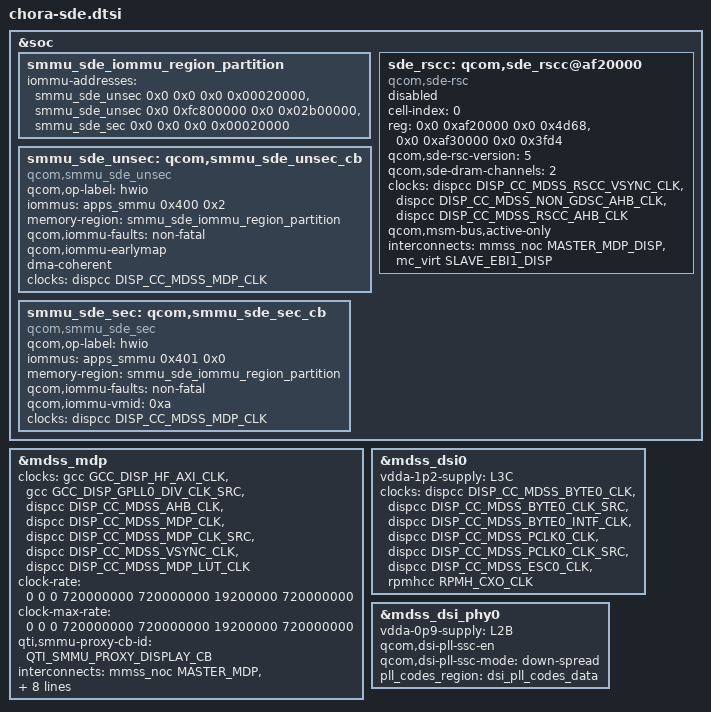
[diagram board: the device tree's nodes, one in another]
// SPDX-License-Identifier: BSD-3-Clause
/*
 * Copyright (c) Qualcomm Technologies, Inc. and/or its subsidiaries.
 */

#include <dt-bindings/interrupt-controller/arm-gic.h>
#include <dt-bindings/soc/qcom,ipcc.h>
#include <dt-bindings/interconnect/qcom,chora.h>
#include <dt-bindings/clock/qcom,chora-dispcc.h>
#include <dt-bindings/clock/qcom,chora-gcc.h>
#include <dt-bindings/clock/qcom,rpmh.h>
#include <dt-bindings/arm/msm/qti-smmu-proxy-dt-ids.h>
#include <dt-bindings/regulator/qcom,rpmh-regulator-levels.h>
#include "chora-sde-common.dtsi"

&soc {
	smmu_sde_iommu_region_partition: smmu_sde_iommu_region_partition {
		iommu-addresses = <&smmu_sde_unsec 0x0 0x0 0x0 0x00020000>,
				  <&smmu_sde_unsec 0x0 0xfc800000 0x0 0x02b00000>,
				  <&smmu_sde_sec 0x0 0x0 0x0 0x00020000>;
	};

	smmu_sde_unsec: qcom,smmu_sde_unsec_cb {
		compatible = "qcom,smmu_sde_unsec";
		qcom,op-label = "hwio";
		status = "ok";
		iommus = <&apps_smmu 0x400 0x2>;
		memory-region = <&smmu_sde_iommu_region_partition>;
		qcom,iommu-faults = "non-fatal";
		qcom,iommu-earlymap; /* for cont-splash */
		dma-coherent;
		clocks = <&dispcc DISP_CC_MDSS_MDP_CLK>;
		clock-names = "mdp_core_clk";
	};

	smmu_sde_sec: qcom,smmu_sde_sec_cb {
		compatible = "qcom,smmu_sde_sec";
		qcom,op-label = "hwio";
		status = "ok";
		iommus = <&apps_smmu 0x401 0x0>;
		memory-region = <&smmu_sde_iommu_region_partition>;
		qcom,iommu-faults = "non-fatal";
		qcom,iommu-vmid = <0xa>;
		clocks = <&dispcc DISP_CC_MDSS_MDP_CLK>;
		clock-names = "mdp_core_clk";
	};

	sde_rscc: qcom,sde_rscc@af20000 {
		cell-index = <0>;
		compatible = "qcom,sde-rsc";
		status = "disabled";
		reg = <0x0 0xaf20000 0x0 0x4d68>,
			<0x0 0xaf30000 0x0 0x3fd4>;
		reg-names = "drv", "wrapper";
		qcom,sde-rsc-version = <5>;

		qcom,sde-dram-channels = <2>;

		clocks = <&dispcc DISP_CC_MDSS_RSCC_VSYNC_CLK>,
			<&dispcc DISP_CC_MDSS_NON_GDSC_AHB_CLK>,
			<&dispcc DISP_CC_MDSS_RSCC_AHB_CLK>;

		clock-names = "vsync_clk", "gdsc_clk", "iface_clk";

		qcom,msm-bus,active-only;
		interconnects = <&mmss_noc MASTER_MDP_DISP &mc_virt SLAVE_EBI1_DISP>;
		interconnect-names = "qcom,sde-data-bus0";
	};
};

&mdss_mdp {
	clocks =
		<&gcc GCC_DISP_HF_AXI_CLK>,
		<&gcc GCC_DISP_GPLL0_DIV_CLK_SRC>,
		<&dispcc DISP_CC_MDSS_AHB_CLK>,
		<&dispcc DISP_CC_MDSS_MDP_CLK>,
		<&dispcc DISP_CC_MDSS_MDP_CLK_SRC>,
		<&dispcc DISP_CC_MDSS_VSYNC_CLK>,
		<&dispcc DISP_CC_MDSS_MDP_LUT_CLK>;

	clock-names = "gcc_bus", "div_clk",
			"iface_clk", "branch_clk", "core_clk", "vsync_clk",
			"lut_clk";
	clock-rate = <0 0 0 720000000 720000000 19200000 720000000>;
	clock-max-rate = <0 0 0 720000000 720000000 19200000 720000000>;

	qti,smmu-proxy-cb-id = <QTI_SMMU_PROXY_DISPLAY_CB>;

	/* data and reg bus scale settings */
	interconnects = <&mmss_noc MASTER_MDP &gem_noc SLAVE_LLCC>,
			<&mc_virt MASTER_LLCC &mc_virt SLAVE_EBI1>,
			<&gem_noc MASTER_APPSS_PROC
				&cnoc_main SLAVE_DISPLAY_CFG>;
	interconnect-names = "qcom,sde-data-bus0",
			"qcom,sde-ebi-bus", "qcom,sde-reg-bus";

	power-domains = <&dispcc DISP_CC_MDSS_CORE_GDSC>, <&dispcc DISP_CC_MDSS_CORE_INT2_GDSC>;
	power-domain-names = "core_gdsc", "core_int2_gdsc";

	qcom,sde-has-idle-pc;

	qcom,sde-ib-bw-vote = <2500000 0 1600000>;
};

&mdss_dsi0 {
	vdda-1p2-supply = <&L3C>;
	clocks = <&dispcc DISP_CC_MDSS_BYTE0_CLK>,
		<&dispcc DISP_CC_MDSS_BYTE0_CLK_SRC>,
		<&dispcc DISP_CC_MDSS_BYTE0_INTF_CLK>,
		<&dispcc DISP_CC_MDSS_PCLK0_CLK>,
		<&dispcc DISP_CC_MDSS_PCLK0_CLK_SRC>,
		<&dispcc DISP_CC_MDSS_ESC0_CLK>,
		<&rpmhcc RPMH_CXO_CLK>;
	clock-names = "byte_clk", "byte_clk_rcg", "byte_intf_clk",
			"pixel_clk", "pixel_clk_rcg", "esc_clk", "xo";
};

&mdss_dsi_phy0 {
	vdda-0p9-supply = <&L2B>;
	qcom,dsi-pll-ssc-en;
	qcom,dsi-pll-ssc-mode = "down-spread";
	pll_codes_region = <&dsi_pll_codes_data>;
};
